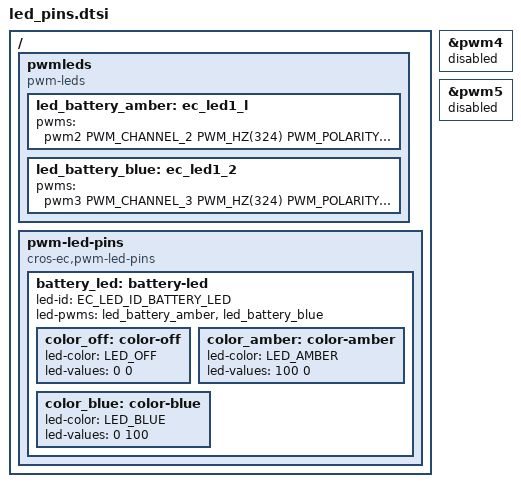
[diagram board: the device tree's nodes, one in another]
/* Copyright 2024 The ChromiumOS Authors
 * Use of this source code is governed by a BSD-style license that can be
 * found in the LICENSE file.
 */

/ {
	pwmleds {
		compatible = "pwm-leds";
		led_battery_amber: ec_led1_l {
			pwms = <&pwm2 PWM_CHANNEL_2 PWM_HZ(324) PWM_POLARITY_INVERTED>;
		};
		led_battery_blue: ec_led1_2 {
			pwms = <&pwm3 PWM_CHANNEL_3 PWM_HZ(324) PWM_POLARITY_INVERTED>;
		};
	};

	pwm-led-pins {
		compatible = "cros-ec,pwm-led-pins";

		battery_led: battery-led {
			led-id = "EC_LED_ID_BATTERY_LED";
			led-pwms = <&led_battery_amber
				    &led_battery_blue>;

			color_off: color-off {
				led-color = "LED_OFF";
				led-values = <0 0>;
			};

			color_amber: color-amber {
				led-color = "LED_AMBER";
				led-values = <100 0>;
			};

			color_blue: color-blue {
				led-color = "LED_BLUE";
				led-values = <0 100>;
			};
		};
	};
};

&pwm4 {
	status = "disabled";
};

&pwm5 {
	status = "disabled";
};
